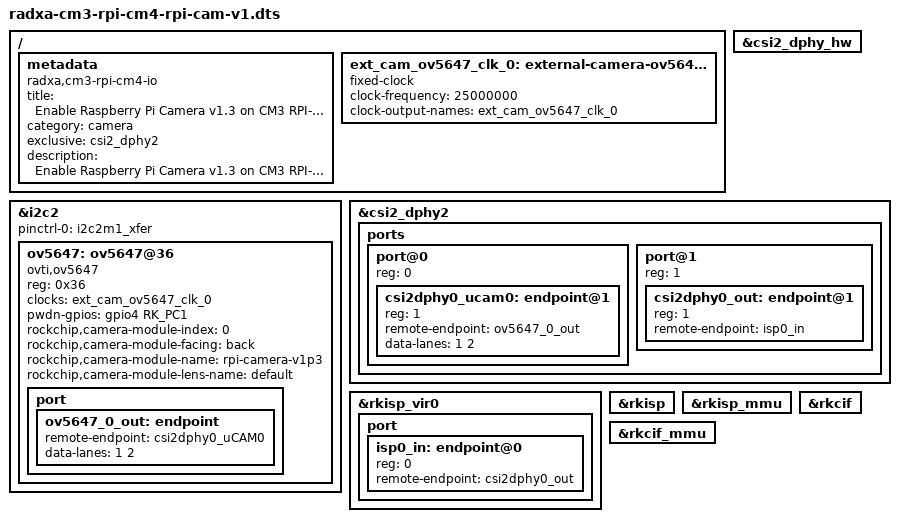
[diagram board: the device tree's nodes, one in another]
/dts-v1/;
/plugin/;

#include <dt-bindings/gpio/gpio.h>
#include <dt-bindings/pinctrl/rockchip.h>

/ {
	metadata {
		title = "Enable Raspberry Pi Camera v1.3 on CM3 RPI-IO v1.34+ CAM0";
		compatible = "radxa,cm3-rpi-cm4-io";
		category = "camera";
		exclusive = "csi2_dphy2";
		description = "Enable Raspberry Pi Camera v1.3 on CM3 RPI-IO v1.34+ CAM0.";
	};

	fragment@0 {
		target-path = "/";

		__overlay__ {
			ext_cam_ov5647_clk_0: external-camera-ov5647-clock-0 {
				status = "okay";
				compatible = "fixed-clock";
				clock-frequency = <25000000>;
				clock-output-names = "ext_cam_ov5647_clk_0";
				#clock-cells = <0>;
			};
		};
	};

	fragment@1 {
		target = <&i2c2>;

		__overlay__ {
			status = "okay";
			pinctrl-names = "default";
			pinctrl-0 = <&i2c2m1_xfer>;
			#address-cells = <1>;
			#size-cells = <0>;

			ov5647: ov5647@36 {
				status = "okay";
				compatible = "ovti,ov5647";
				reg = <0x36>;
				clocks = <&ext_cam_ov5647_clk_0>;
				clock-names = "ext_cam_ov5647_clk_0";
				pwdn-gpios = <&gpio4 RK_PC1 GPIO_ACTIVE_HIGH>;
				rockchip,camera-module-index = <0>;
				rockchip,camera-module-facing = "back";
				rockchip,camera-module-name = "rpi-camera-v1p3";
				rockchip,camera-module-lens-name = "default";

				port {
					ov5647_0_out: endpoint {
						remote-endpoint = <&csi2dphy0_uCAM0>;
						data-lanes = <1 2>;
					};
				};
			};
		};
	};

	fragment@2 {
		target = <&csi2_dphy_hw>;

		__overlay__ {
			status = "okay";
		};
	};

	fragment@3 {
		target = <&csi2_dphy2>;

		__overlay__ {
			status = "okay";

			ports {
				#address-cells = <1>;
				#size-cells = <0>;

				port@0 {
					reg = <0>;
					#address-cells = <1>;
					#size-cells = <0>;

					csi2dphy0_ucam0: endpoint@1 {
						reg = <1>;
						remote-endpoint = <&ov5647_0_out>;
						data-lanes = <1 2>;
					};
				};

				port@1 {
					reg = <1>;
					#address-cells = <1>;
					#size-cells = <0>;

					csi2dphy0_out: endpoint@1 {
						reg = <1>;
						remote-endpoint = <&isp0_in>;
					};
				};
			};
		};
	};

	fragment@4 {
		target = <&rkisp_vir0>;

		__overlay__ {
			status = "okay";

			port {
				#address-cells = <1>;
				#size-cells = <0>;

				isp0_in: endpoint@0 {
					reg = <0>;
					remote-endpoint = <&csi2dphy0_out>;
				};
			};
		};
	};

	fragment@5 {
		target = <&rkisp>;

		__overlay__ {
			status = "okay";
		};
	};

	fragment@6 {
		target = <&rkisp_mmu>;

		__overlay__ {
			status = "okay";
		};
	};

	fragment@7 {
		target = <&rkcif_mmu>;

		__overlay__ {
			status = "okay";
		};
	};

	fragment@8 {
		target = <&rkcif>;

		__overlay__ {
			status = "okay";
		};
	};

};
